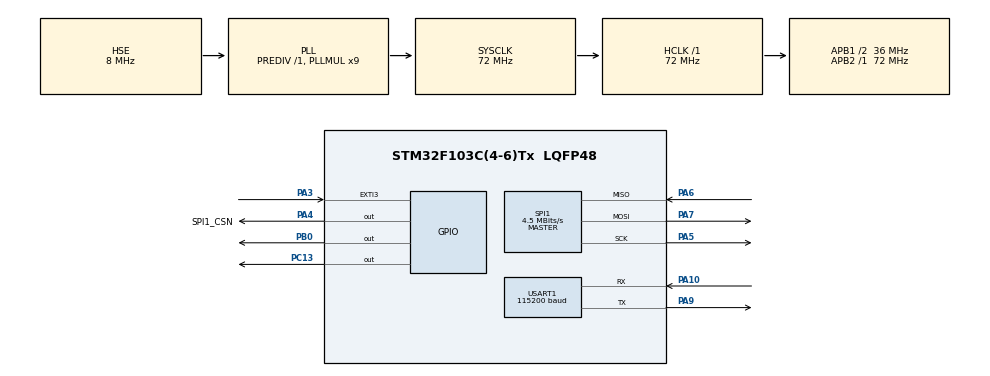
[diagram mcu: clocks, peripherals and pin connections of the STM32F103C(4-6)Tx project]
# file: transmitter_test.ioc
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Mcu.Family=STM32F1
Mcu.Name=STM32F103C(4-6)Tx
Mcu.Package=LQFP48
NVIC.EXTI3_IRQn=true\:0\:0\:false\:false\:true\:true\:true\:true
NVIC.PriorityGroup=NVIC_PRIORITYGROUP_4
NVIC.USART1_IRQn=true\:0\:0\:false\:false\:true\:true\:true\:true
PA10.Mode=Asynchronous
PA10.Signal=USART1_RX
PA13.Mode=Serial_Wire
PA13.Signal=SYS_JTMS-SWDIO
PA14.Mode=Serial_Wire
PA14.Signal=SYS_JTCK-SWCLK
PA3.GPIO_ModeDefaultEXTI=GPIO_MODE_IT_FALLING
PA3.Signal=GPXTI3
PA4.GPIO_Label=SPI1_CSN
PA4.GPIO_Speed=GPIO_SPEED_FREQ_HIGH
PA4.PinState=GPIO_PIN_SET
PA4.Signal=GPIO_Output
PA5.Mode=Full_Duplex_Master
PA5.Signal=SPI1_SCK
PA6.Mode=Full_Duplex_Master
PA6.Signal=SPI1_MISO
PA7.Mode=Full_Duplex_Master
PA7.Signal=SPI1_MOSI
PA9.Mode=Asynchronous
PA9.Signal=USART1_TX
PB0.Signal=GPIO_Output
PC13-TAMPER-RTC.Signal=GPIO_Output
PD0-OSC_IN.Mode=HSE-External-Oscillator
PD0-OSC_IN.Signal=RCC_OSC_IN
PD1-OSC_OUT.Mode=HSE-External-Oscillator
PD1-OSC_OUT.Signal=RCC_OSC_OUT
ProjectManager.HeapSize=0x200
ProjectManager.StackSize=0x400
ProjectManager.TargetToolchain=STM32CubeIDE
RCC.AHBFreq_Value=72000000
RCC.APB1CLKDivider=RCC_HCLK_DIV2
RCC.APB1Freq_Value=36000000
RCC.APB1TimFreq_Value=72000000
RCC.APB2Freq_Value=72000000
RCC.APB2TimFreq_Value=72000000
RCC.FLatency=FLASH_LATENCY_2
RCC.HCLKFreq_Value=72000000
RCC.PLLMUL=RCC_PLL_MUL9
RCC.PLLSourceVirtual=RCC_PLLSOURCE_HSE
RCC.SYSCLKFreq_VALUE=72000000
RCC.SYSCLKSource=RCC_SYSCLKSOURCE_PLLCLK
RCC.USBFreq_Value=72000000
SPI1.BaudRatePrescaler=SPI_BAUDRATEPRESCALER_16
SPI1.CLKPhase=SPI_PHASE_1EDGE
SPI1.CLKPolarity=SPI_POLARITY_LOW
SPI1.CRCCalculation=SPI_CRCCALCULATION_DISABLE
SPI1.CalculateBaudRate=4.5 MBits/s
SPI1.DataSize=SPI_DATASIZE_8BIT
SPI1.Direction=SPI_DIRECTION_2LINES
SPI1.FirstBit=SPI_FIRSTBIT_MSB
SPI1.Mode=SPI_MODE_MASTER
SPI1.NSS=SPI_NSS_SOFT
SPI1.TIMode=SPI_TIMODE_DISABLE
SPI1.VirtualType=VM_MASTER
USART1.BaudRate=115200
USART1.Mode=MODE_TX_RX
USART1.Parity=PARITY_NONE
USART1.StopBits=STOPBITS_1
USART1.VirtualMode=VM_ASYNC
USART1.WordLength=WORDLENGTH_8B
board=custom

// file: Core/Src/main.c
/* USER CODE BEGIN Header */
/**
 ******************************************************************************
 * @file           : main.c
 * @brief          : Main program body
 ******************************************************************************
 * @attention
 *
 * Copyright (c) 2023 STMicroelectronics.
 * All rights reserved.
 *
 * This software is licensed under terms that can be found in the LICENSE file
 * in the root directory of this software component.
 * If no LICENSE file comes with this software, it is provided AS-IS.
 *
 ******************************************************************************
 */
/* USER CODE END Header */
#include "main.h"
#include "spi.h"
#include "usart.h"
#include "gpio.h"

/* USER CODE BEGIN Includes */
#include <stdio.h>

#include "nrf24l01.h"

/* USER CODE END Includes */

void SystemClock_Config(void);

/* USER CODE BEGIN 0 */
uint8_t TxBuffer[NRF24L01_PAYLOAD_LENGTH] = {0};

void HAL_GPIO_EXTI_Callback(uint16_t GPIO_Pin)
{
	if(GPIO_Pin == NRF24L01_IRQ_GPIO_PIN)
	{
		NRF24L01_TxIRQHandle(2000);
	}
}

/* USER CODE END 0 */

int main(void)
{

  /* MCU Configuration--------------------------------------------------------*/

  /* Reset of all peripherals, Initializes the Flash interface and the Systick. */
  HAL_Init();

  /* Configure the system clock */
  SystemClock_Config();

  /* Initialize all configured peripherals */
  MX_GPIO_Init();
  MX_SPI1_Init();
  MX_USART1_UART_Init();
  /* USER CODE BEGIN 2 */

	//uint8_t TxAddress0[5] = {0x78, 0x78, 0x78, 0x78, 0x78};
	uint8_t TxAddress1[5] = {0xB3, 0xB4, 0xB5, 0xB6, 0xCD};

	NRF24L01_TxInit(100, NRF24L01_DATA_RATE_1MBPS, 2000);

	NRF24L01_SetTxAddress(TxAddress1, 2000);

  /* USER CODE END 2 */

  /* Infinite loop */
  /* USER CODE BEGIN WHILE */
	while (1)
	{

//		sprintf((char *)TxBuffer, "Transmitter Time:%07ld", (HAL_GetTick() / 1000));

		NRF24L01_TxTransmit(TxBuffer, 2000);

		HAL_GPIO_TogglePin(GPIOC, GPIO_PIN_13);

		HAL_Delay(100);

    /* USER CODE END WHILE */

	}
}

void SystemClock_Config(void)
{
  RCC_OscInitTypeDef RCC_OscInitStruct = {0};
  RCC_ClkInitTypeDef RCC_ClkInitStruct = {0};

  /** Initializes the RCC Oscillators according to the specified parameters
  * in the RCC_OscInitTypeDef structure.
  */
  RCC_OscInitStruct.OscillatorType = RCC_OSCILLATORTYPE_HSE;
  RCC_OscInitStruct.HSEState = RCC_HSE_ON;
  RCC_OscInitStruct.HSEPredivValue = RCC_HSE_PREDIV_DIV1;
  RCC_OscInitStruct.HSIState = RCC_HSI_ON;
  RCC_OscInitStruct.PLL.PLLState = RCC_PLL_ON;
  RCC_OscInitStruct.PLL.PLLSource = RCC_PLLSOURCE_HSE;
  RCC_OscInitStruct.PLL.PLLMUL = RCC_PLL_MUL9;
  if (HAL_RCC_OscConfig(&RCC_OscInitStruct) != HAL_OK)
  {
    Error_Handler();
  }

  /** Initializes the CPU, AHB and APB buses clocks
  */
  RCC_ClkInitStruct.ClockType = RCC_CLOCKTYPE_HCLK|RCC_CLOCKTYPE_SYSCLK
                              |RCC_CLOCKTYPE_PCLK1|RCC_CLOCKTYPE_PCLK2;
  RCC_ClkInitStruct.SYSCLKSource = RCC_SYSCLKSOURCE_PLLCLK;
  RCC_ClkInitStruct.AHBCLKDivider = RCC_SYSCLK_DIV1;
  RCC_ClkInitStruct.APB1CLKDivider = RCC_HCLK_DIV2;
  RCC_ClkInitStruct.APB2CLKDivider = RCC_HCLK_DIV1;

  if (HAL_RCC_ClockConfig(&RCC_ClkInitStruct, FLASH_LATENCY_2) != HAL_OK)
  {
    Error_Handler();
  }
}

void Error_Handler(void)
{
	__disable_irq();
	while (1)
	{
	}
}
